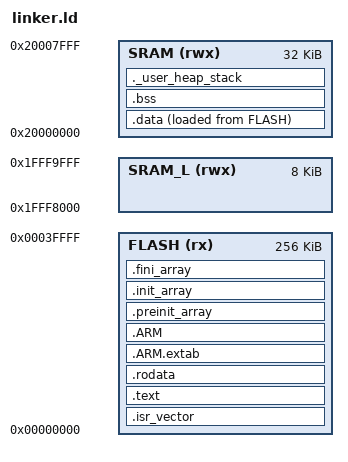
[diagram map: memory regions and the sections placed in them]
/*
 * Linker script for S32K312/S32K344 with Cortex-M7
 * Memory layout based on S32K3xx reference manual
 */

/* Entry Point */
ENTRY(Reset_Handler)

/* Memory layout for S32K312/S32K344 */
MEMORY
{
    /* Flash memory - 256KB for S32K312, 512KB for S32K344 */
    FLASH (rx) : ORIGIN = 0x00000000, LENGTH = 256K
    
    /* SRAM - 32KB for S32K312, 64KB for S32K344 */
    SRAM (rwx) : ORIGIN = 0x20000000, LENGTH = 32K
    
    /* SRAM_L - Additional SRAM for S32K344 */
    SRAM_L (rwx) : ORIGIN = 0x1FFF8000, LENGTH = 8K
}

/* Stack and heap sizes */
_estack = ORIGIN(SRAM) + LENGTH(SRAM);    /* End of SRAM */
_Min_Heap_Size = 0x200;                   /* Required amount of heap */
_Min_Stack_Size = 0x400;                  /* Required amount of stack */

/* Define output sections */
SECTIONS
{
    /* The startup code goes first into FLASH */
    .isr_vector :
    {
        . = ALIGN(4);
        KEEP(*(.isr_vector)) /* Startup code */
        . = ALIGN(4);
    } >FLASH

    /* The program code and other readonly data goes into FLASH */
    .text :
    {
        . = ALIGN(4);
        *(.text)           /* .text sections (code) */
        *(.text*)          /* .text* sections (code) */
        *(.glue_7)         /* glue arm to thumb code */
        *(.glue_7t)        /* glue thumb to arm code */
        *(.eh_frame)

        KEEP (*(.init))
        KEEP (*(.fini))

        . = ALIGN(4);
        _etext = .;        /* define a global symbol at end of code */
    } >FLASH

    /* Constant data goes into FLASH */
    .rodata :
    {
        . = ALIGN(4);
        *(.rodata)         /* .rodata sections (constants, strings, etc.) */
        *(.rodata*)        /* .rodata* sections (constants, strings, etc.) */
        . = ALIGN(4);
    } >FLASH

    .ARM.extab   : { *(.ARM.extab* .gnu.linkonce.armextab.*) } >FLASH
    .ARM : {
        __exidx_start = .;
        *(.ARM.exidx*)
        __exidx_end = .;
    } >FLASH

    .preinit_array     :
    {
        PROVIDE_HIDDEN (__preinit_array_start = .);
        KEEP (*(.preinit_array*))
        PROVIDE_HIDDEN (__preinit_array_end = .);
    } >FLASH

    .init_array :
    {
        PROVIDE_HIDDEN (__init_array_start = .);
        KEEP (*(SORT(.init_array.*)))
        KEEP (*(.init_array*))
        PROVIDE_HIDDEN (__init_array_end = .);
    } >FLASH

    .fini_array :
    {
        PROVIDE_HIDDEN (__fini_array_start = .);
        KEEP (*(SORT(.fini_array.*)))
        KEEP (*(.fini_array*))
        PROVIDE_HIDDEN (__fini_array_end = .);
    } >FLASH

    /* Used by the startup to initialize data */
    _sidata = LOADADDR(.data);

    /* Initialized data sections goes into RAM, load LMA copy after code */
    .data : 
    {
        . = ALIGN(4);
        _sdata = .;        /* create a global symbol at data start */
        *(.data)           /* .data sections */
        *(.data*)          /* .data* sections */

        . = ALIGN(4);
        _edata = .;        /* define a global symbol at data end */
    } >SRAM AT> FLASH

    /* Uninitialized data section */
    . = ALIGN(4);
    .bss :
    {
        /* This is used by the startup in order to initialize the .bss section */
        _sbss = .;         /* define a global symbol at bss start */
        __bss_start__ = _sbss;
        *(.bss)
        *(.bss*)
        *(COMMON)

        . = ALIGN(4);
        _ebss = .;         /* define a global symbol at bss end */
        __bss_end__ = _ebss;
    } >SRAM

    /* User_heap_stack section, used to check that there is enough RAM left */
    ._user_heap_stack :
    {
        . = ALIGN(8);
        PROVIDE ( end = . );
        PROVIDE ( _end = . );
        . = . + _Min_Heap_Size;
        . = . + _Min_Stack_Size;
        . = ALIGN(8);
    } >SRAM

    /* Remove information from the standard libraries */
    /DISCARD/ :
    {
        libc.a ( * )
        libm.a ( * )
        libgcc.a ( * )
    }

    .ARM.attributes 0 : { *(.ARM.attributes) }
}
